VERSION ""

NS_ :

BS_:

BU_: ECU_BCM ECU_BMS ECU_ENGINE ECU_BRAKE Vector__XXX

BO_ 80 Power_01: 8 ECU_BCM
 SG_ Clamp15Status : 0|1@1+ (1,0) [0|1] "" Vector__XXX
 SG_ BatteryVoltageCAN : 8|8@1+ (0.1,0) [0|24] "V" Vector__XXX

BO_ 256 Engine_01: 8 ECU_ENGINE
 SG_ EngineSpeed : 16|16@1+ (1,0) [0|8000] "rpm" Vector__XXX

BO_ 288 Brake_01: 8 ECU_BRAKE
 SG_ VehicleSpeed : 0|16@1+ (1,0) [0|300] "km/h" Vector__XXX
 SG_ BrakePedalPosition : 16|8@1+ (1,0) [0|100] "%" Vector__XXX

BO_ 512 Body_01: 8 ECU_BCM
 SG_ DoorContactStatus : 0|1@1+ (1,0) [0|1] "" Vector__XXX

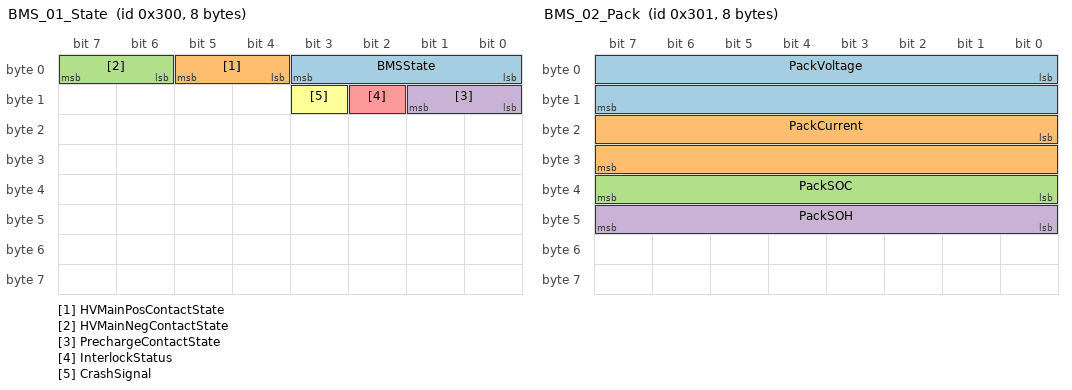
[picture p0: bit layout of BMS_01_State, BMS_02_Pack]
BO_ 768 BMS_01_State: 8 ECU_BMS
 SG_ BMSState : 0|4@1+ (1,0) [0|10] "" Vector__XXX
 SG_ HVMainPosContactState : 4|2@1+ (1,0) [0|2] "" Vector__XXX
 SG_ HVMainNegContactState : 6|2@1+ (1,0) [0|2] "" Vector__XXX
 SG_ PrechargeContactState : 8|2@1+ (1,0) [0|2] "" Vector__XXX
 SG_ InterlockStatus : 10|1@1+ (1,0) [0|1] "" Vector__XXX
 SG_ CrashSignal : 11|1@1+ (1,0) [0|1] "" Vector__XXX

BO_ 769 BMS_02_Pack: 8 ECU_BMS
 SG_ PackVoltage : 0|16@1+ (0.1,0) [0|1000] "V" Vector__XXX
 SG_ PackCurrent : 16|16@1- (0.1,0) [-1000|1000] "A" Vector__XXX
 SG_ PackSOC : 32|8@1+ (0.5,0) [0|100] "%" Vector__XXX
 SG_ PackSOH : 40|8@1+ (0.5,0) [0|100] "%" Vector__XXX

BO_ 770 BMS_03_Limits: 8 ECU_BMS
 SG_ MaxChargeCurrent : 0|16@1+ (0.1,0) [0|500] "A" Vector__XXX
 SG_ MaxDischargeCurrent : 16|16@1+ (0.1,0) [0|800] "A" Vector__XXX

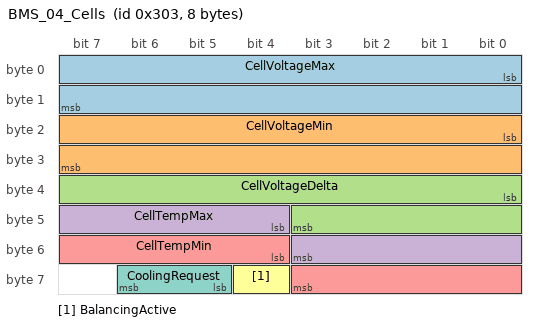
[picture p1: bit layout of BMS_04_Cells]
BO_ 771 BMS_04_Cells: 8 ECU_BMS
 SG_ CellVoltageMax : 0|16@1+ (0.001,0) [0|5] "V" Vector__XXX
 SG_ CellVoltageMin : 16|16@1+ (0.001,0) [0|5] "V" Vector__XXX
 SG_ CellVoltageDelta : 32|12@1+ (1,0) [0|2000] "mV" Vector__XXX
 SG_ CellTempMax : 44|8@1+ (1,-40) [-40|120] "degC" Vector__XXX
 SG_ CellTempMin : 52|8@1+ (1,-40) [-40|120] "degC" Vector__XXX
 SG_ BalancingActive : 60|1@1+ (1,0) [0|1] "" Vector__XXX
 SG_ CoolingRequest : 61|2@1+ (1,0) [0|2] "" Vector__XXX

BO_ 772 BMS_05_Safety: 8 ECU_BMS
 SG_ IsolationResistance : 0|16@1+ (1,0) [0|5000] "kOhm" Vector__XXX
 SG_ IsolationStatus : 16|2@1+ (1,0) [0|2] "" Vector__XXX

CM_ "Powertrain_BMS_CAN";
CM_ BO_ 80 "Status Spannungsversorgung und Klemmen";
CM_ SG_ 80 Clamp15Status "Zuendungsstatus Klemme 15 (0=aus, 1=an)";
CM_ SG_ 80 BatteryVoltageCAN "Batteriespannung ueber CAN uebertragen";
CM_ BO_ 256 "Motor- und Drehzahl-Botschaft";
CM_ SG_ 256 EngineSpeed "Motordrehzahl in Umdrehungen pro Minute";
CM_ BO_ 288 "Fahrzeuggeschwindigkeit und Bremsendaten";
CM_ SG_ 288 VehicleSpeed "Fahrzeuggeschwindigkeit in km/h";
CM_ SG_ 288 BrakePedalPosition "Bremspedalstellung in Prozent";
CM_ BO_ 512 "Karosserie- und Tuerkontakte";
CM_ SG_ 512 DoorContactStatus "Tuerkontaktstatus (0=geschlossen, 1=offen)";
CM_ BO_ 768 "BMS Betriebszustand und Schuetze";
CM_ SG_ 768 BMSState "BMS Zustand (0=Init, 1=Standby, 2=Precharge, 3=DriveReady, 4=Charge, 5=Fault)";
CM_ SG_ 768 HVMainPosContactState "Hauptschuetz HV+ Status (0=Offen, 1=Geschlossen, 2=Fehler)";
CM_ SG_ 768 HVMainNegContactState "Hauptschuetz HV- Status (0=Offen, 1=Geschlossen, 2=Fehler)";
CM_ SG_ 768 PrechargeContactState "Vorladeschuetz Status (0=Offen, 1=Geschlossen, 2=Fehler)";
CM_ SG_ 768 InterlockStatus "HV-Interlock Schleife (0=Offen/Unterbrochen, 1=Geschlossen)";
CM_ SG_ 768 CrashSignal "Crash-Signal (0=Kein Crash, 1=Crash erkannt)";
CM_ BO_ 769 "Batteriepack Gesamtspannung, Strom und SOC/SOH";
CM_ SG_ 769 PackVoltage "Gesamtspannung der Hochvoltbatterie in Volt";
CM_ SG_ 769 PackCurrent "Batteriestrom in Ampere (negativ=Laden, positiv=Entladen)";
CM_ SG_ 769 PackSOC "Ladezustand (State of Charge) in Prozent";
CM_ SG_ 769 PackSOH "Gesundheitszustand (State of Health) in Prozent";
CM_ BO_ 770 "Lade- und Entladestrombegrenzungen (Derating)";
CM_ SG_ 770 MaxChargeCurrent "Maximal zulaessiger Ladestrom (Derating-Grenze) in Ampere";
CM_ SG_ 770 MaxDischargeCurrent "Maximal zulaessiger Entladestrom (Derating-Grenze) in Ampere";
CM_ BO_ 771 "Zellspannungs- und Zelltemperaturueberwachung";
CM_ SG_ 771 CellVoltageMax "Hoechste gemessene Einzelzellspannung im Pack in Volt";
CM_ SG_ 771 CellVoltageMin "Niedrigste gemessene Einzelzellspannung im Pack in Volt";
CM_ SG_ 771 CellVoltageDelta "Spannungsdifferenz zwischen hoechster und niedrigster Zelle in mV";
CM_ SG_ 771 CellTempMax "Hoechste gemessene Zelltemperatur in Grad Celsius";
CM_ SG_ 771 CellTempMin "Niedrigste gemessene Zelltemperatur in Grad Celsius";
CM_ SG_ 771 BalancingActive "Zell-Balancing Status (0=Inaktiv, 1=Aktiv)";
CM_ SG_ 771 CoolingRequest "Kuehlanforderung an Thermomanagement (0=Aus, 1=Stufe 1, 2=Stufe 2)";
CM_ BO_ 772 "Sicherheitsueberwachung: Isolationswiderstand und Interlock";
CM_ SG_ 772 IsolationResistance "Gemessener Isolationswiderstand zwischen HV und Chassis in kOhm";
CM_ SG_ 772 IsolationStatus "Isolationsueberwachungs-Status (0=Normal, 1=Warnung, 2=Fehler)";

BA_DEF_ "BusType" STRING ;
BA_DEF_ "Baudrate" INT 0 1000000;
BA_DEF_ BO_ "GenMsgCycleTime" INT 0 65535;
BA_DEF_ SG_ "GenSigStartValue" FLOAT -10000000 10000000;

BA_DEF_DEF_ "BusType" "CAN";
BA_DEF_DEF_ "Baudrate" 500000;
BA_DEF_DEF_ "GenMsgCycleTime" 0;
BA_DEF_DEF_ "GenSigStartValue" 0;

BA_ "GenMsgCycleTime" BO_ 80 100;
BA_ "GenMsgCycleTime" BO_ 256 10;
BA_ "GenMsgCycleTime" BO_ 288 20;
BA_ "GenMsgCycleTime" BO_ 512 50;
BA_ "GenMsgCycleTime" BO_ 768 20;
BA_ "GenMsgCycleTime" BO_ 769 20;
BA_ "GenMsgCycleTime" BO_ 770 50;
BA_ "GenMsgCycleTime" BO_ 771 50;
BA_ "GenMsgCycleTime" BO_ 772 100;

BA_ "GenSigStartValue" SG_ 80 BatteryVoltageCAN 13.5;
BA_ "GenSigStartValue" SG_ 768 BMSState 1;
BA_ "GenSigStartValue" SG_ 768 InterlockStatus 1;
BA_ "GenSigStartValue" SG_ 769 PackVoltage 400.0;
BA_ "GenSigStartValue" SG_ 769 PackSOC 80.0;
BA_ "GenSigStartValue" SG_ 769 PackSOH 98.0;
BA_ "GenSigStartValue" SG_ 770 MaxChargeCurrent 150.0;
BA_ "GenSigStartValue" SG_ 770 MaxDischargeCurrent 300.0;
BA_ "GenSigStartValue" SG_ 771 CellVoltageMax 3.7;
BA_ "GenSigStartValue" SG_ 771 CellVoltageMin 3.7;
BA_ "GenSigStartValue" SG_ 771 CellTempMax 25.0;
BA_ "GenSigStartValue" SG_ 771 CellTempMin 23.0;
BA_ "GenSigStartValue" SG_ 772 IsolationResistance 1500.0;

VAL_ 80 Clamp15Status 0 "Aus" 1 "An" ;
VAL_ 512 DoorContactStatus 0 "Geschlossen" 1 "Offen" ;
VAL_ 768 BMSState 0 "Init" 1 "Standby" 2 "Precharge" 3 "DriveReady" 4 "Charge" 5 "Fault" ;
VAL_ 768 HVMainPosContactState 0 "Offen" 1 "Geschlossen" 2 "Fehler" ;
VAL_ 768 HVMainNegContactState 0 "Offen" 1 "Geschlossen" 2 "Fehler" ;
VAL_ 768 PrechargeContactState 0 "Offen" 1 "Geschlossen" 2 "Fehler" ;
VAL_ 768 InterlockStatus 0 "Offen" 1 "Geschlossen" ;
VAL_ 768 CrashSignal 0 "Kein Crash" 1 "Crash erkannt" ;
VAL_ 771 BalancingActive 0 "Inaktiv" 1 "Aktiv" ;
VAL_ 771 CoolingRequest 0 "Aus" 1 "Stufe 1" 2 "Stufe 2" ;
VAL_ 772 IsolationStatus 0 "Normal" 1 "Warnung" 2 "Fehler" ;
